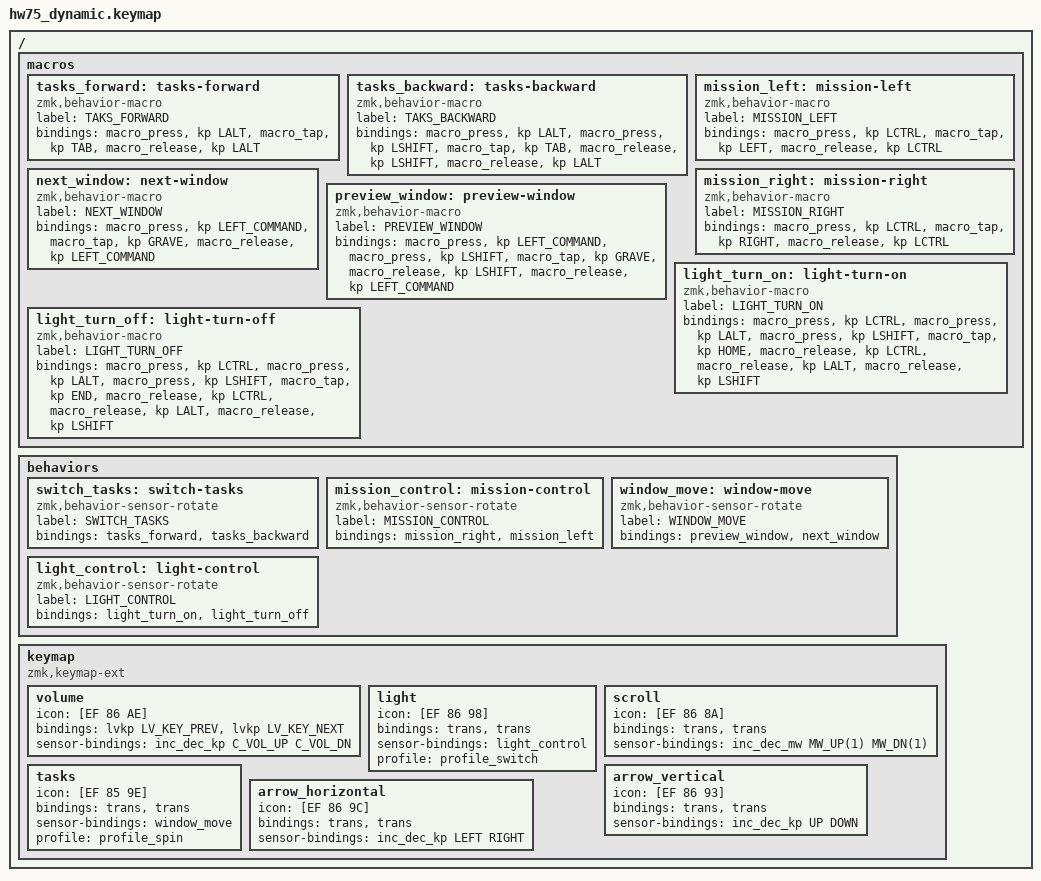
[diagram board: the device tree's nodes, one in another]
/*
 * Copyright (c) 2022 The ZMK Contributors
 * SPDX-License-Identifier: MIT
 */

#include <behaviors.dtsi>
#include <behaviors/lvgl_key_press.dtsi>
#include <behaviors/sensor_rotate_mouse_wheel.dtsi>
#include <dt-bindings/zmk/keys.h>
#include <dt-bindings/zmk/rgb.h>
#include <dt-bindings/zmk/lvgl.h>
#include <dt-bindings/zmk/mouse.h>

/ {
	macros {
		tasks_forward: tasks-forward {
			label = "TAKS_FORWARD";
			compatible = "zmk,behavior-macro";
			#binding-cells = <0>;
			bindings = <&macro_press   &kp LALT>,
				   <&macro_tap     &kp TAB>,
				   <&macro_release &kp LALT>;
		};

		tasks_backward: tasks-backward {
			label = "TAKS_BACKWARD";
			compatible = "zmk,behavior-macro";
			#binding-cells = <0>;
			bindings = <&macro_press   &kp LALT>,
				   <&macro_press   &kp LSHIFT>,
				   <&macro_tap     &kp TAB>,
				   <&macro_release &kp LSHIFT>,
				   <&macro_release &kp LALT>;
		};
		mission_left: mission-left {
			label = "MISSION_LEFT";
			compatible = "zmk,behavior-macro";
			#binding-cells = <0>;
			bindings = <&macro_press   &kp LCTRL>,
				   <&macro_tap     &kp LEFT>,
				   <&macro_release &kp LCTRL>;
		};
		mission_right: mission-right {
			label = "MISSION_RIGHT";
			compatible = "zmk,behavior-macro";
			#binding-cells = <0>;
			bindings = <&macro_press   &kp LCTRL>,
				   <&macro_tap     &kp RIGHT>,
				   <&macro_release &kp LCTRL>;
		};
		next_window: next-window{
			label = "NEXT_WINDOW";
			compatible = "zmk,behavior-macro";
			#binding-cells = <0>;
			bindings = <&macro_press   &kp LEFT_COMMAND>,
				   <&macro_tap     &kp GRAVE>,
				   <&macro_release &kp LEFT_COMMAND>;
		};
		preview_window: preview-window {
			label = "PREVIEW_WINDOW";
			compatible = "zmk,behavior-macro";
			#binding-cells = <0>;
			bindings = <&macro_press   &kp LEFT_COMMAND>,
				   <&macro_press   &kp LSHIFT>,
				   <&macro_tap     &kp GRAVE>,
				   <&macro_release &kp LSHIFT>,
				   <&macro_release &kp LEFT_COMMAND>;
		};
		light_turn_on: light-turn-on {
			label = "LIGHT_TURN_ON";
			compatible = "zmk,behavior-macro";
			#binding-cells = <0>;
			bindings = <&macro_press   &kp LCTRL>,
				   <&macro_press   &kp LALT>,
				   <&macro_press   &kp LSHIFT>,
				   <&macro_tap     &kp HOME>,
				   <&macro_release &kp LCTRL>,
				   <&macro_release &kp LALT>,
				   <&macro_release &kp LSHIFT>;
		};
		light_turn_off: light-turn-off {
			label = "LIGHT_TURN_OFF";
			compatible = "zmk,behavior-macro";
			#binding-cells = <0>;
			bindings = <&macro_press   &kp LCTRL>,
				   <&macro_press   &kp LALT>,
				   <&macro_press   &kp LSHIFT>,
				   <&macro_tap     &kp END>,
				   <&macro_release &kp LCTRL>,
				   <&macro_release &kp LALT>,
				   <&macro_release &kp LSHIFT>;
		};
	};

	behaviors {
		switch_tasks: switch-tasks {
			compatible = "zmk,behavior-sensor-rotate";
			label = "SWITCH_TASKS";
			#sensor-binding-cells = <0>;
			bindings = <&tasks_forward>, <&tasks_backward>;
		};
		mission_control: mission-control {
			compatible = "zmk,behavior-sensor-rotate";
			label = "MISSION_CONTROL";
			#sensor-binding-cells = <0>;
			bindings = <&mission_right>, <&mission_left>;
		};
		window_move: window-move {
			compatible = "zmk,behavior-sensor-rotate";
			label = "WINDOW_MOVE";
			#sensor-binding-cells = <0>;
			bindings = <&preview_window>, <&next_window>;
		};
		light_control: light-control {
			compatible = "zmk,behavior-sensor-rotate";
			label = "LIGHT_CONTROL";
			#sensor-binding-cells = <0>;
			bindings = <&light_turn_on>, <&light_turn_off>;
		};
	};

	keymap {
		compatible = "zmk,keymap-ext", "zmk,keymap";

		volume {
			label = "音量";
			icon = [EF 86 AE];
			bindings = <&lvkp LV_KEY_PREV &lvkp LV_KEY_NEXT>;
			sensor-bindings = <&inc_dec_kp C_VOL_UP C_VOL_DN>;
		};

		light {
			label = "台灯";
			icon = [EF 86 98];
			bindings = <&trans &trans>;
			sensor-bindings = <&light_control>;
			profile = <&profile_switch>;
		};

		scroll {
			label = "滚动";
			icon = [EF 86 8A];
			bindings = <&trans &trans>;
			sensor-bindings = <&inc_dec_mw MW_UP(1) MW_DN(1)>;
		};

		tasks {
			label = "窗口";
			icon = [EF 85 9E];
			bindings = <&trans &trans>;
			sensor-bindings = <&window_move>;
			profile = <&profile_spin>;
		};

		arrow_vertical {
			label = "上下";
			icon = [EF 86 93];
			bindings = <&trans &trans>;
			sensor-bindings = <&inc_dec_kp UP DOWN>;
		};

		arrow_horizontal {
			label = "左右";
			icon = [EF 86 9C];
			bindings = <&trans &trans>;
			sensor-bindings = <&inc_dec_kp LEFT RIGHT>;
		};
	};
};
